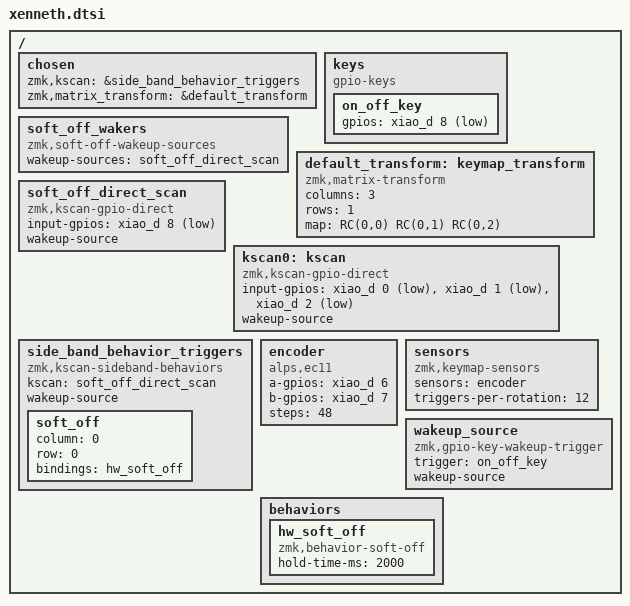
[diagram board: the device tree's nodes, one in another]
/*
 * Copyright (c) 2022 The ZMK Contributors
 *
 * SPDX-License-Identifier: MIT
 */

#include <dt-bindings/zmk/matrix_transform.h>

/ {
	chosen {
		zmk,kscan = &kscan0;
		zmk,matrix_transform = &default_transform;
		zmk,kscan = &side_band_behavior_triggers;
	};


	keys {
		compatible = "gpio-keys";
		on_off_key: on_off_key {
			gpios = <&xiao_d 8 (GPIO_ACTIVE_LOW | GPIO_PULL_UP)>;
		};
	};

	soft_off_wakers {
        compatible = "zmk,soft-off-wakeup-sources";
        wakeup-sources = <&soft_off_direct_scan>;
    };

	default_transform: keymap_transform {
		compatible = "zmk,matrix-transform";
		columns = <3>;
		rows = <1>;
		map = <
			RC(0,0)  
			RC(0,1)  
			RC(0,2)
		>;
	};

	soft_off_direct_scan: soft_off_direct_scan {
        compatible = "zmk,kscan-gpio-direct";
        input-gpios = <&xiao_d  8 (GPIO_ACTIVE_LOW | GPIO_PULL_UP)>;
        wakeup-source;
	};

	kscan0: kscan {
		compatible = "zmk,kscan-gpio-direct";
		input-gpios =
			<&xiao_d  0 (GPIO_ACTIVE_LOW | GPIO_PULL_UP)>,
			<&xiao_d  1 (GPIO_ACTIVE_LOW | GPIO_PULL_UP)>,
			<&xiao_d  2 (GPIO_ACTIVE_LOW | GPIO_PULL_UP)>;
		wakeup-source;
	};

	side_band_behavior_triggers: side_band_behavior_triggers {
        compatible = "zmk,kscan-sideband-behaviors";

        kscan = <&soft_off_direct_scan>;
        wakeup-source;

        soft_off {
            column = <0>;
            row = <0>;
            bindings = <&hw_soft_off>;
        };
    };

	encoder: encoder {
		compatible = "alps,ec11";
		a-gpios = <&xiao_d 6 (GPIO_ACTIVE_HIGH | GPIO_PULL_UP)>;
		b-gpios = <&xiao_d 7 (GPIO_ACTIVE_HIGH | GPIO_PULL_UP)>;
		steps = <48>;
		//status = "disabled";
	};
	
	sensors {
		compatible = "zmk,keymap-sensors";
		sensors = <&encoder>;
		triggers-per-rotation = <12>;
	};

	wakeup_source: wakeup_source {
        compatible = "zmk,gpio-key-wakeup-trigger";

        trigger = <&on_off_key>;
        wakeup-source;
    };

	behaviors {
        hw_soft_off: hw_soft_off {
            compatible = "zmk,behavior-soft-off";
            #binding-cells = <0>;
            hold-time-ms = <2000>;
        };
    };
};
